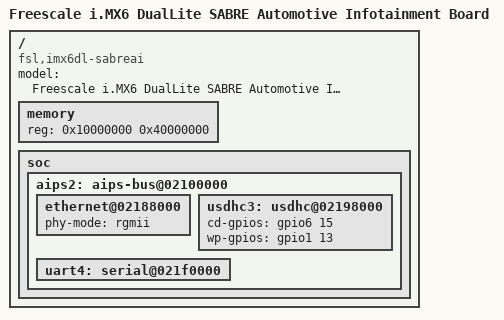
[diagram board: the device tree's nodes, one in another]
/*
 * Copyright 2012 Freescale Semiconductor, Inc.
 * Copyright 2012 Linaro Ltd.
 *
 * The code contained herein is licensed under the GNU General Public
 * License. You may obtain a copy of the GNU General Public License
 * Version 2 or later at the following locations:
 *
 * http://www.opensource.org/licenses/gpl-license.html
 * http://www.gnu.org/copyleft/gpl.html
 */

/dts-v1/;
/include/ "imx6dl.dtsi"

/ {
	model = "Freescale i.MX6 DualLite SABRE Automotive Infotainment Board";
	compatible = "fsl,imx6dl-sabreai", "fsl,imx6dl";

	memory {
		reg = <0x10000000 0x40000000>;
	};

	soc {
		aips2: aips-bus@02100000 {
			ethernet@02188000 {
				phy-mode = "rgmii";
				status = "okay";
			};

			usdhc3: usdhc@02198000 {
				cd-gpios = <&gpio6 15 0>;
				wp-gpios = <&gpio1 13 0>;
				status = "okay";
			};

			uart4: serial@021f0000 {
				status = "okay";
			};
		};
	};
};
